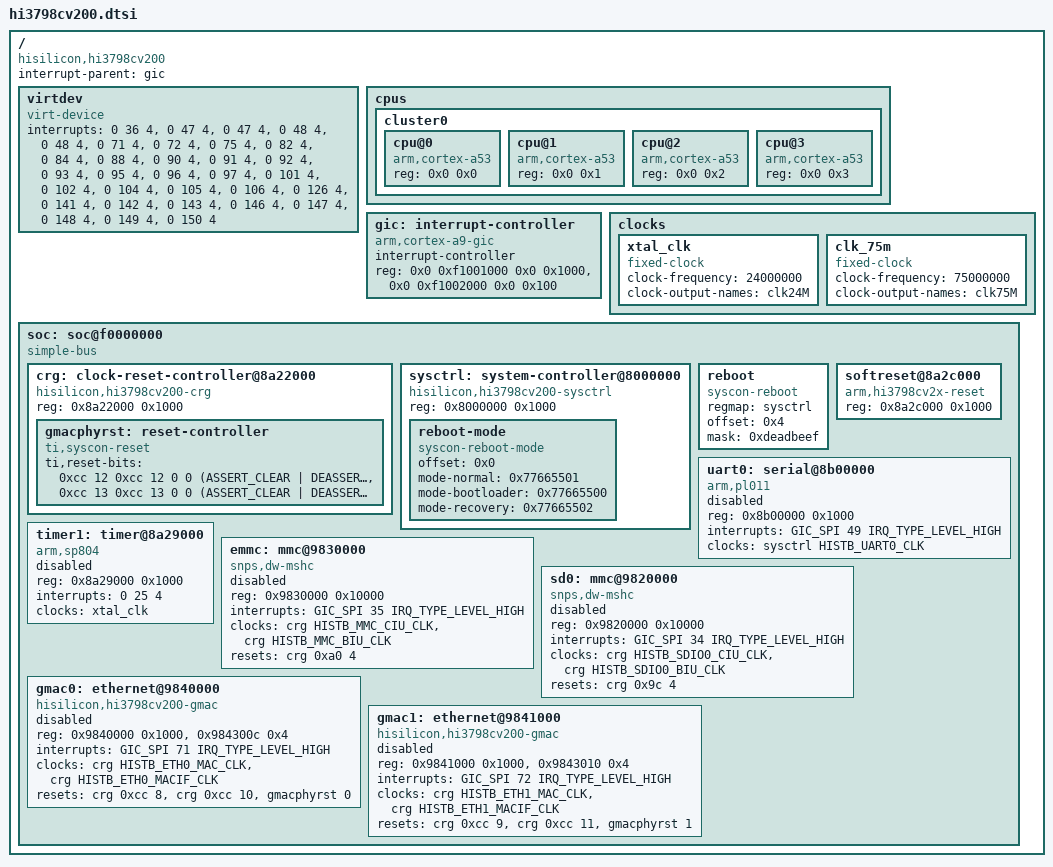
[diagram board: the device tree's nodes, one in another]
/*
 * DTS File for HiSilicon Hi3798cv200 SoC.
 *
 * Copyright (c) 2016-2017 HiSilicon Technologies Co., Ltd.
 *
 * Released under the GPLv2 only.
 * SPDX-License-Identifier: GPL-2.0
 */

#include <dt-bindings/clock/histb-clock.h>
#include <dt-bindings/gpio/gpio.h>
#include <dt-bindings/interrupt-controller/arm-gic.h>
#include <dt-bindings/phy/phy.h>
#include <dt-bindings/reset/ti-syscon.h>

/ {
	compatible = "hisilicon,hi3798cv200";
	interrupt-parent = <&gic>;
	#address-cells = <2>;
	#size-cells = <2>;

	virtdev {
		compatible = "virt-device";
		interrupts = <0 36 4>,  /* "sci0"          */
			     <0 47 4>,  /* "ir_std"        */
			     <0 47 4>,  /* "ir_s2"         */
			     <0 48 4>,  /* "keyled_ct1642" */
			     <0 48 4>,  /* "keyled_std"    */
			     <0 71 4>,  /* "gsf0"          */
			     <0 72 4>,  /* "gsf1"          */
			     <0 75 4>,  /* "multicipher"   */
			     <0 82 4>,  /* "dmx"           */
			     <0 84 4>,  /* "aiao"          */
			     <0 88 4>,  /* "hdmi"          */
			     <0 90 4>,  /* "vdp"           */
			     <0 91 4>,  /* "tde"           */
			     <0 92 4>,  /* "gfx2d"         */
			     <0 93 4>,  /* "vpss0"         */
			     <0 95 4>,  /* "vdec_vdh"      */
			     <0 96 4>,  /* "png"           */
			     <0 97 4>,  /* "jpeg"          */
			     <0 101 4>, /* "venc"          */
			     <0 102 4>, /* "jpge"          */
			     <0 104 4>, /* "vdec_scd"      */
			     <0 105 4>, /* "vdec_vdh_safe" */
			     <0 106 4>, /* "vdec_scd_safe" */
			     <0 126 4>, /* "cipher"        */
			     <0 141 4>, /* "gpu_mmu"       */
			     <0 142 4>, /* "gpu_job"       */
			     <0 143 4>, /* "gpu"           */
			     <0 146 4>, /* "SecInvokeirq"  */
			     <0 147 4>, /* "hdmi_cec"      */
			     <0 148 4>, /* "mmu_vdh_safe"  */
			     <0 149 4>, /* "mmu_vdh"       */
			     <0 150 4>; /* "pastc"         */
		interrupt-names = /* 36  */ "sci0",
				  /* 47  */ "ir_std",
				  /* 47  */ "ir_s2",
				  /* 48  */ "keyled_ct1642",
				  /* 48  */ "keyled_std",
				  /* 71  */ "gsf0",
				  /* 72  */ "gsf1",
				  /* 75  */ "multicipher",
				  /* 82  */ "dmx",
				  /* 84  */ "aiao",
				  /* 88  */ "hdmi",
				  /* 90  */ "vdp",
				  /* 91  */ "tde",
				  /* 92  */ "gfx2d",
				  /* 93  */ "vpss0",
				  /* 95  */ "vdec_vdh",
				  /* 96  */ "png",
				  /* 97  */ "jpeg",
				  /* 101 */ "venc",
				  /* 102 */ "jpge",
				  /* 104 */ "vdec_scd",
				  /* 105 */ "vdec_vdh_safe",
				  /* 106 */ "vdec_scd_safe",
				  /* 126 */ "cipher",
				  /* 141 */ "gpu_mmu",
				  /* 142 */ "gpu_job",
				  /* 143 */ "gpu",
				  /* 146 */ "SecInvokeirq",
				  /* 147 */ "hdmi_cec",
				  /* 148 */ "mmu_vdh_safe",
				  /* 149 */ "mmu_vdh",
				  /* 150 */ "pastc";
	};
	
	cpus {
		cluster0: cluster0 { 
		#address-cells = <2>;
		#size-cells = <0>;

		cpu@0 {
			compatible = "arm,cortex-a53";
			device_type = "cpu";
			reg = <0x0 0x0>;
			/*enable-method = "psci";*/
		};

		cpu@1 {
			compatible = "arm,cortex-a53";
			device_type = "cpu";
			reg = <0x0 0x1>;
			/*enable-method = "psci";*/
		};

		cpu@2 {
			compatible = "arm,cortex-a53";
			device_type = "cpu";
			reg = <0x0 0x2>;
			/*enable-method = "psci";*/
		};

		cpu@3 {
			compatible = "arm,cortex-a53";
			device_type = "cpu";
			reg = <0x0 0x3>;
			/*enable-method = "psci";*/
		};
		};
	};

	gic: interrupt-controller {
		compatible = "arm,cortex-a9-gic";
		#interrupt-cells = <3>;
		#address-cells = <0>;
		interrupt-controller;
		/*reg = <0xf1001000 0x1000>,
		      <0xf1002000 0x100>;*/
		reg = <0x0 0xf1001000 0x0 0x1000>,  /* GICD */
		      <0x0 0xf1002000 0x0 0x100>;   /* GICC */ 
	};

	clocks {
		xtal_clk: xtal_clk {
			compatible = "fixed-clock";
			#clock-cells = <0>;
			clock-frequency = <24000000>;
			clock-output-names = "clk24M";
		};

		clk_75m: clk_75m{
			compatible = "fixed-clock";
			#clock-cells = <0>;
			clock-frequency = <75000000>;
			clock-output-names = "clk75M";
		};
	};

	soc: soc@f0000000 {
		compatible = "simple-bus";
		#address-cells = <1>;
		#size-cells = <1>;
		ranges = <0x0 0x0 0xf0000000 0x10000000>;

		crg: clock-reset-controller@8a22000 {
			compatible = "hisilicon,hi3798cv200-crg", "syscon", "simple-mfd";
			reg = <0x8a22000 0x1000>;
			#clock-cells = <1>;
			#reset-cells = <2>;
			
			gmacphyrst: reset-controller {
				compatible = "ti,syscon-reset";
				#reset-cells = <1>;
				ti,reset-bits =
					<0xcc 12 0xcc 12 0 0 (ASSERT_CLEAR |
					 DEASSERT_SET|STATUS_NONE)>,
					<0xcc 13 0xcc 13 0 0 (ASSERT_CLEAR |
					 DEASSERT_SET|STATUS_NONE)>;
			};
		};

		sysctrl: system-controller@8000000 {
			compatible = "hisilicon,hi3798cv200-sysctrl", "syscon";
			reg = <0x8000000 0x1000>;
			#clock-cells = <1>;
			#reset-cells = <2>;
			
			reboot-mode {
				compatible = "syscon-reboot-mode";
				offset = <0x0>;
				mode-normal	= <0x77665501>;
				mode-bootloader	= <0x77665500>;
				mode-recovery	= <0x77665502>;
			};
		};

		reboot {
			compatible = "syscon-reboot";
			regmap = <&sysctrl>;
			offset = <0x4>;
			mask = <0xdeadbeef>;
		};

		softreset@8a2c000 {
			compatible = "arm,hi3798cv2x-reset";
			reg = <0x8a2c000 0x1000>;
		};
		
		uart0: serial@8b00000 {
			compatible = "arm,pl011", "arm,primecell";
			reg = <0x8b00000 0x1000>;
			interrupts = <GIC_SPI 49 IRQ_TYPE_LEVEL_HIGH>;
			clocks = <&sysctrl HISTB_UART0_CLK>;
			clock-names = "apb_pclk";
			status = "disabled";
		};

		timer1: timer@8a29000 {
			compatible = "arm,sp804", "arm,primecell";
			reg = <0x8a29000 0x1000>;
			/* timer10 & timer11 */
			interrupts = <0 25 4>;
			clocks = <&xtal_clk>; /*<&sysctrl HISTB_TIMER01_CLK>;*/
			clock-names = "apb_pclk"; 
			status = "disabled";
		};

		emmc: mmc@9830000 {
			compatible = "snps,dw-mshc";
			reg = <0x9830000 0x10000>;
			interrupts = <GIC_SPI 35 IRQ_TYPE_LEVEL_HIGH>;
			clocks = <&crg HISTB_MMC_CIU_CLK>,
				<&crg HISTB_MMC_BIU_CLK>;
			clock-names = "ciu", "biu";
			resets = <&crg 0xa0 4>;
			reset-names = "reset";
			status = "disabled";
		};

		sd0: mmc@9820000 {
			compatible = "snps,dw-mshc";
			reg = <0x9820000 0x10000>;
			interrupts = <GIC_SPI 34 IRQ_TYPE_LEVEL_HIGH>;
			clocks = <&crg HISTB_SDIO0_CIU_CLK>,
				<&crg HISTB_SDIO0_BIU_CLK>;
			clock-names = "ciu", "biu";
			resets = <&crg 0x9c 4>;
			reset-names = "reset";
			status = "disabled";
		};

		gmac0: ethernet@9840000 {
			compatible = "hisilicon,hi3798cv200-gmac", "hisilicon,hisi-gmac-v2";
			reg = <0x9840000 0x1000>,
			      <0x984300c 0x4>;
			interrupts = <GIC_SPI 71 IRQ_TYPE_LEVEL_HIGH>;
			clocks = <&crg HISTB_ETH0_MAC_CLK>,
				 <&crg HISTB_ETH0_MACIF_CLK>;
			clock-names = "mac_core", "mac_ifc";
			resets = <&crg 0xcc 8>,
				 <&crg 0xcc 10>,
				 <&gmacphyrst 0>;
			reset-names = "mac_core", "mac_ifc", "phy";
			status = "disabled";
		};

		gmac1: ethernet@9841000 {
			compatible = "hisilicon,hi3798cv200-gmac", "hisilicon,hisi-gmac-v2";
			reg = <0x9841000 0x1000>,
			      <0x9843010 0x4>;
			interrupts = <GIC_SPI 72 IRQ_TYPE_LEVEL_HIGH>;
			clocks = <&crg HISTB_ETH1_MAC_CLK>,
				 <&crg HISTB_ETH1_MACIF_CLK>;
			clock-names = "mac_core", "mac_ifc";
			resets = <&crg 0xcc 9>,
				 <&crg 0xcc 11>,
				 <&gmacphyrst 1>;
			reset-names = "mac_core", "mac_ifc", "phy";
			status = "disabled";
		};


	};
};

